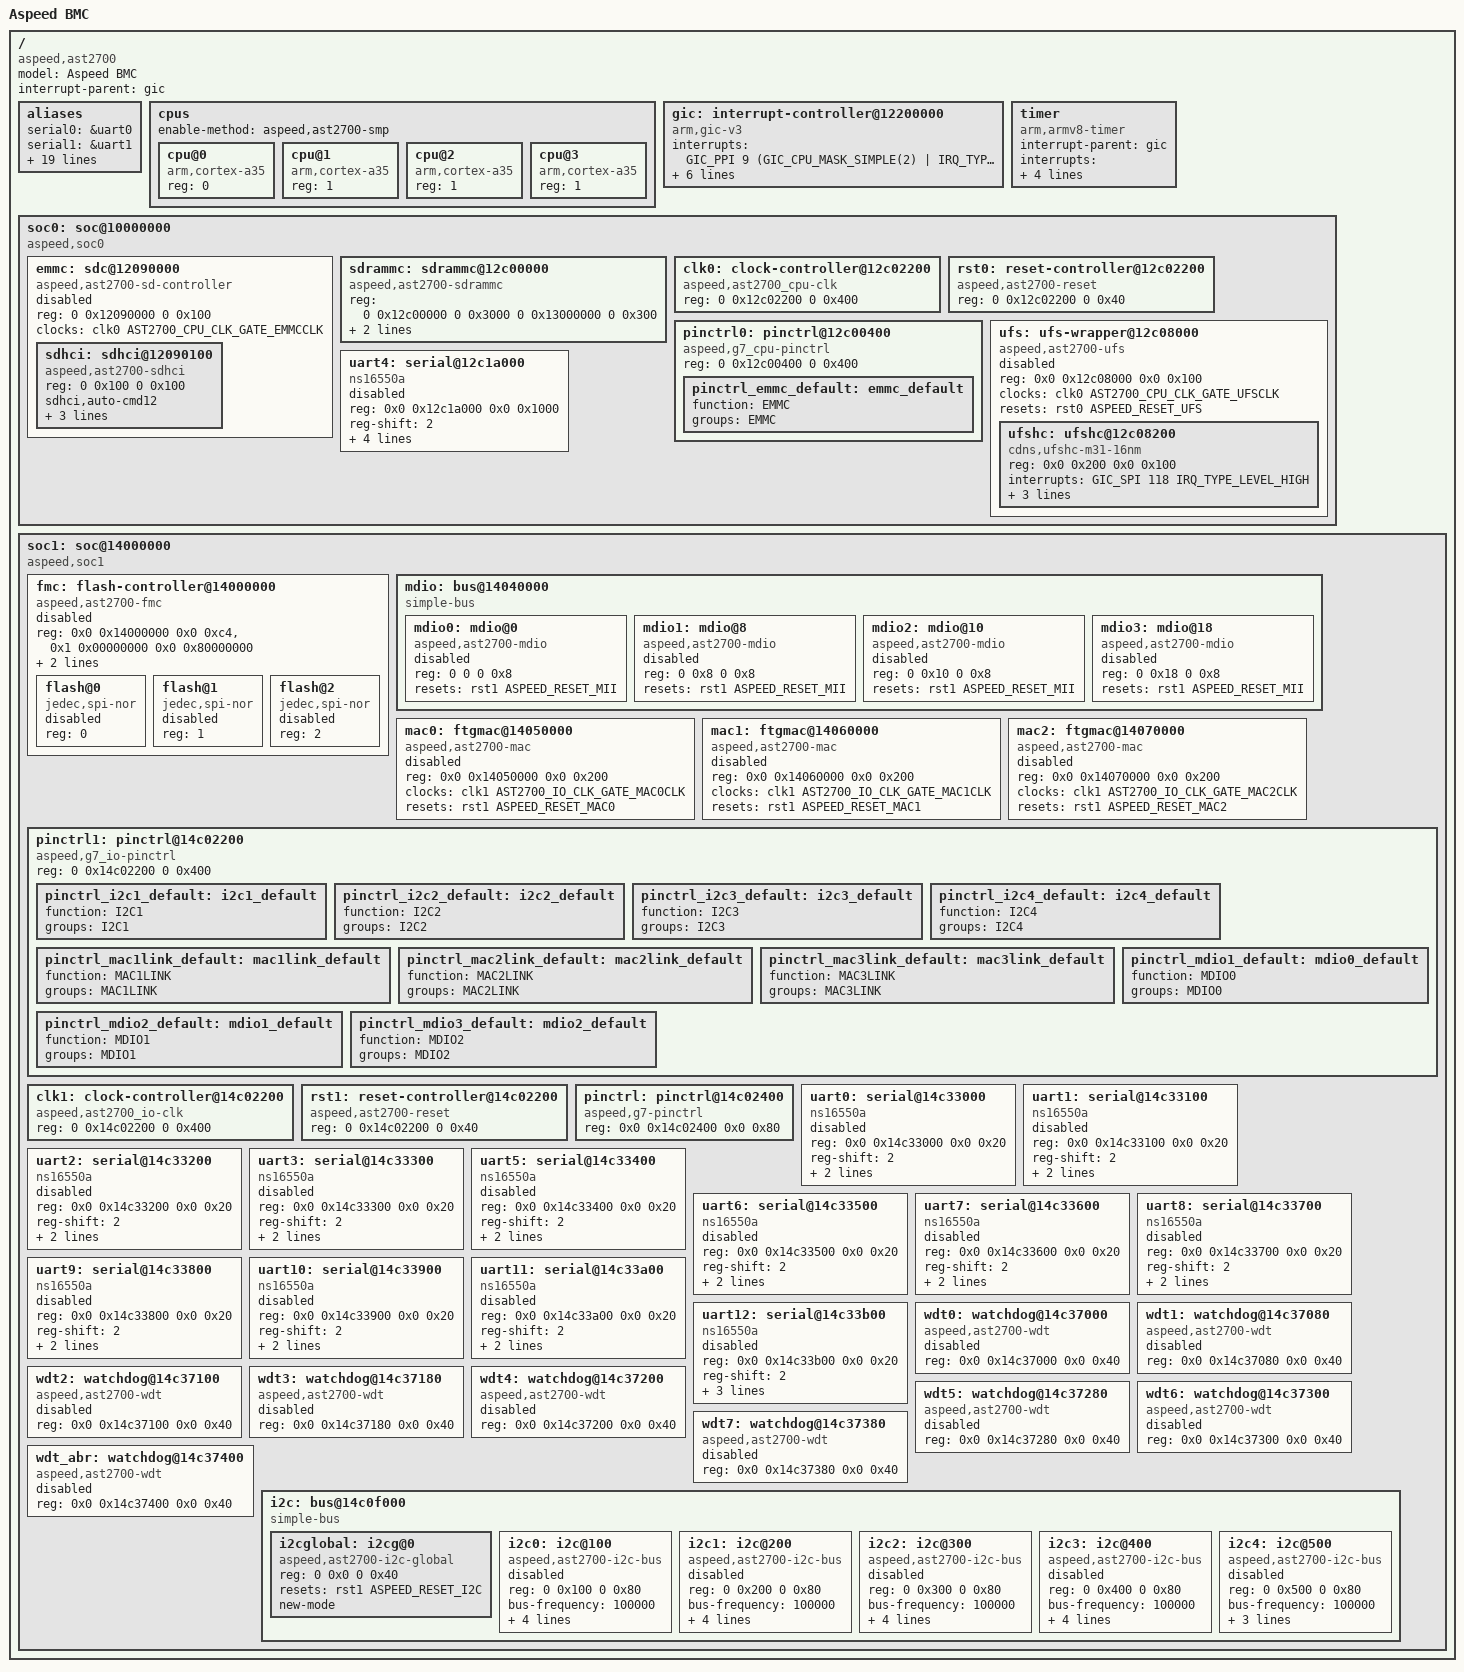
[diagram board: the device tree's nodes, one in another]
// SPDX-License-Identifier: GPL-2.0+
#include <dt-bindings/interrupt-controller/arm-gic.h>
#include <dt-bindings/gpio/aspeed-gpio.h>
#include <dt-bindings/clock/ast2700-clock.h>
#include <dt-bindings/reset/ast2700-reset.h>
#include "skeleton.dtsi"

/ {
	model = "Aspeed BMC";
	compatible = "aspeed,ast2700";
	#address-cells = <2>;
	#size-cells = <2>;
	interrupt-parent = <&gic>;

	aliases {
		serial0 = &uart0;
		serial1 = &uart1;
		serial2 = &uart2;
		serial3 = &uart3;
		serial4 = &uart4;
		serial5 = &uart5;
		serial6 = &uart6;
		serial7 = &uart7;
		serial8 = &uart8;
		serial9 = &uart9;
		serial10 = &uart10;
		serial11 = &uart11;
		serial12 = &uart12;
		i2c0 = &i2c0;
		i2c1 = &i2c1;
		i2c2 = &i2c2;
		i2c3 = &i2c3;
		i2c4 = &i2c4;
		ethernet0 = &mac0;
		ethernet1 = &mac1;
		ethernet2 = &mac2;
	};

	cpus {
		#address-cells = <1>;
		#size-cells = <0>;
		enable-method = "aspeed,ast2700-smp";

		cpu@0 {
			compatible = "arm,cortex-a35";
			device_type = "cpu";
			reg = <0>;
		};

		cpu@1 {
			compatible = "arm,cortex-a35";
			device_type = "cpu";
			reg = <1>;
		};

		cpu@2 {
			compatible = "arm,cortex-a35";
			device_type = "cpu";
			reg = <1>;
		};

		cpu@3 {
			compatible = "arm,cortex-a35";
			device_type = "cpu";
			reg = <1>;
		};

	};

	gic: interrupt-controller@12200000 {
		compatible = "arm,gic-v3";
		interrupts = <GIC_PPI 9 (GIC_CPU_MASK_SIMPLE(2) | IRQ_TYPE_LEVEL_HIGH)>;
		#interrupt-cells = <3>;
		interrupt-controller;
		interrupt-parent = <&gic>;
		#redistributor-regions = <1>;
		reg =	<0 0x12200000 0 0x10000>,		//GICD
			<0 0x12280000 0 0x80000>,		//GICR
			<0 0x40440000 0 0x1000>;		//GICC
	};

	timer {
		compatible = "arm,armv8-timer";
		interrupt-parent = <&gic>;
		interrupts = <GIC_PPI 13 (GIC_CPU_MASK_SIMPLE(2) | IRQ_TYPE_LEVEL_LOW)>,
				<GIC_PPI 14 (GIC_CPU_MASK_SIMPLE(2) | IRQ_TYPE_LEVEL_LOW)>,
				<GIC_PPI 11 (GIC_CPU_MASK_SIMPLE(2) | IRQ_TYPE_LEVEL_LOW)>,
				<GIC_PPI 10 (GIC_CPU_MASK_SIMPLE(2) | IRQ_TYPE_LEVEL_LOW)>;
	};

	soc0: soc@10000000 {
		compatible = "aspeed,soc0","simple-bus";
		#address-cells = <2>;
		#size-cells = <2>;
		ranges;

		emmc: sdc@12090000 {
			compatible = "aspeed,ast2700-sd-controller";
			reg = <0 0x12090000 0 0x100>;
			#address-cells = <2>;
			#size-cells = <2>;
			ranges = <0 0 0 0x12090000 0 0x10000>;
			clocks = <&clk0 AST2700_CPU_CLK_GATE_EMMCCLK>;
			status = "disable";

			sdhci: sdhci@12090100 {
				compatible = "aspeed,ast2700-sdhci";
				reg = <0 0x100 0 0x100>;
				sdhci,auto-cmd12;
				#interrupts = <GIC_SPI 15 IRQ_TYPE_LEVEL_HIGH>;
				clocks = <&clk0 AST2700_CPU_CLK_EMMC>;
				resets = <&rst0 ASPEED_RESET_EMMC>;
				//pinctrl-names = "default";
				//pinctrl-0 = <&pinctrl_emmc_default>;
			};
		};

		sdrammc: sdrammc@12c00000 {
			compatible = "aspeed,ast2700-sdrammc";
			reg = <0 0x12c00000 0 0x3000 0 0x13000000 0 0x300 >;
			clocks = <&clk0 AST2700_CPU_CLK_MPLL>;
			resets = <&rst0 ASPEED_RESET_SDRAM>;
		};

		clk0: clock-controller@12c02200 {
			compatible = "aspeed,ast2700_cpu-clk";
			reg = <0 0x12c02200 0 0x400>;
			#clock-cells = <1>;
		};

		rst0: reset-controller@12c02200 {
			compatible = "aspeed,ast2700-reset";
			reg = <0 0x12c02200 0 0x40>;
			#reset-cells = <1>;
		};

		pinctrl0: pinctrl@12c00400 {
			compatible = "aspeed,g7_cpu-pinctrl";
			reg = <0 0x12c00400 0 0x400>;
		};

		ufs: ufs-wrapper@12c08000 {
			compatible = "aspeed,ast2700-ufs";
			reg = <0x0 0x12c08000 0x0 0x100>;
			#address-cells = <2>;
			#size-cells = <2>;
			ranges = <0 0 0 0x12c08000 0 0x400>;
			clocks = <&clk0 AST2700_CPU_CLK_GATE_UFSCLK>;
			resets = <&rst0 ASPEED_RESET_UFS>;
			status = "disable";

			ufshc: ufshc@12c08200 {
				compatible = "cdns,ufshc-m31-16nm", "jedec,ufs-2.0";
				reg = <0x0 0x200 0x0 0x100>;
				interrupts = <GIC_SPI 118 IRQ_TYPE_LEVEL_HIGH>;
				freq-table-hz = <24000000 24000000>;
				clocks = <&clk0 AST2700_CPU_CLK_MPLL>;
				clock-names = "core_clk";
				dma-coherent;
			};
		};

		uart4: serial@12c1a000 {
			compatible = "ns16550a";
			reg = <0x0 0x12c1a000 0x0 0x1000>;
			reg-shift = <2>;
			interrupts = <GIC_SPI 36 IRQ_TYPE_LEVEL_HIGH>;
			clocks = <&clk1 AST2700_CPU_CLK_GATE_UART4CLK>;
			clock-frequency = <1846154>;
			no-loopback-test;
			status = "disabled";
		};
	};

	soc1: soc@14000000 {
		compatible = "aspeed,soc1","simple-bus";
		#address-cells = <2>;
		#size-cells = <2>;
		ranges;

		fmc: flash-controller@14000000 {
			reg = <0x0 0x14000000 0x0 0xc4>,
			      <0x1 0x00000000 0x0 0x80000000>;
			#address-cells = <1>;
			#size-cells = <0>;
			compatible = "aspeed,ast2700-fmc";
			status = "disabled";
			clocks = <&clk1 AST2700_IO_CLK_AHB>;
			num-cs = <3>;

			flash@0 {
				reg = <0>;
				compatible = "jedec,spi-nor";
				status = "disabled";
			};

			flash@1 {
				reg = <1>;
				compatible = "jedec,spi-nor";
				status = "disabled";
			};

			flash@2 {
				reg = <2>;
				compatible = "jedec,spi-nor";
				status = "disabled";
			};
		};

		mdio: bus@14040000 {
			compatible = "simple-bus";
			#address-cells = <2>;
			#size-cells = <2>;
			ranges = <0 0 0 0x14040000 0 0x100>;

			mdio0: mdio@0 {
				compatible = "aspeed,ast2700-mdio";
				reg = <0 0 0 0x8>;
				resets = <&rst1 ASPEED_RESET_MII>;
				status = "disabled";
			};

			mdio1: mdio@8 {
				compatible = "aspeed,ast2700-mdio";
				reg = <0 0x8 0 0x8>;
				resets = <&rst1 ASPEED_RESET_MII>;
				status = "disabled";
			};

			mdio2: mdio@10 {
				compatible = "aspeed,ast2700-mdio";
				reg = <0 0x10 0 0x8>;
				resets = <&rst1 ASPEED_RESET_MII>;
				status = "disabled";
			};

			mdio3: mdio@18 {
				compatible = "aspeed,ast2700-mdio";
				reg = <0 0x18 0 0x8>;
				resets = <&rst1 ASPEED_RESET_MII>;
				status = "disabled";
			};
		};

		mac0: ftgmac@14050000 {
			compatible = "aspeed,ast2700-mac", "faraday,ftgmac100";
			reg = <0x0 0x14050000 0x0 0x200>;
			clocks = <&clk1 AST2700_IO_CLK_GATE_MAC0CLK>;
			resets = <&rst1 ASPEED_RESET_MAC0>;
			status = "disabled";
		};

		mac1: ftgmac@14060000 {
			compatible = "aspeed,ast2700-mac", "faraday,ftgmac100";
			reg = <0x0 0x14060000 0x0 0x200>;
			clocks = <&clk1 AST2700_IO_CLK_GATE_MAC1CLK>;
			resets = <&rst1 ASPEED_RESET_MAC1>;
			status = "disabled";
		};

		mac2: ftgmac@14070000 {
			compatible = "aspeed,ast2700-mac", "faraday,ftgmac100";
			reg = <0x0 0x14070000 0x0 0x200>;
			clocks = <&clk1 AST2700_IO_CLK_GATE_MAC2CLK>;
			resets = <&rst1 ASPEED_RESET_MAC2>;
			status = "disabled";
		};

		pinctrl1: pinctrl@14c02200 {
			compatible = "aspeed,g7_io-pinctrl";
			reg = <0 0x14c02200 0 0x400>;
		};

		clk1: clock-controller@14c02200 {
			compatible = "aspeed,ast2700_io-clk";
			reg = <0 0x14c02200 0 0x400>;
			#clock-cells = <1>;
		};

		rst1: reset-controller@14c02200 {
			compatible = "aspeed,ast2700-reset";
			reg = <0 0x14c02200 0 0x40>;
			#reset-cells = <1>;
		};

		pinctrl: pinctrl@14c02400 {
			compatible = "aspeed,g7-pinctrl";
			reg = <0x0 0x14c02400 0x0 0x80>;
		};

		uart0: serial@14c33000 {
			compatible = "ns16550a";
			reg = <0x0 0x14c33000 0x0 0x20>;
			reg-shift = <2>;
			clocks = <&clk1 AST2700_IO_CLK_GATE_UART0CLK>;
			no-loopback-test;
			status = "disabled";
		};

		uart1: serial@14c33100 {
			compatible = "ns16550a";
			reg = <0x0 0x14c33100 0x0 0x20>;
			reg-shift = <2>;
			clocks = <&clk1 AST2700_IO_CLK_GATE_UART1CLK>;
			no-loopback-test;
			status = "disabled";
		};

		uart2: serial@14c33200 {
			compatible = "ns16550a";
			reg = <0x0 0x14c33200 0x0 0x20>;
			reg-shift = <2>;
			clocks = <&clk1 AST2700_IO_CLK_GATE_UART2CLK>;
			no-loopback-test;
			status = "disabled";
		};

		uart3: serial@14c33300 {
			compatible = "ns16550a";
			reg = <0x0 0x14c33300 0x0 0x20>;
			reg-shift = <2>;
			clocks = <&clk1 AST2700_IO_CLK_GATE_UART3CLK>;
			no-loopback-test;
			status = "disabled";
		};

		uart5: serial@14c33400 {
			compatible = "ns16550a";
			reg = <0x0 0x14c33400 0x0 0x20>;
			reg-shift = <2>;
			clocks = <&clk1 AST2700_IO_CLK_GATE_UART5CLK>;
			no-loopback-test;
			status = "disabled";
		};

		uart6: serial@14c33500 {
			compatible = "ns16550a";
			reg = <0x0 0x14c33500 0x0 0x20>;
			reg-shift = <2>;
			clocks = <&clk1 AST2700_IO_CLK_GATE_UART6CLK>;
			no-loopback-test;
			status = "disabled";
		};

		uart7: serial@14c33600 {
			compatible = "ns16550a";
			reg = <0x0 0x14c33600 0x0 0x20>;
			reg-shift = <2>;
			clocks = <&clk1 AST2700_IO_CLK_GATE_UART7CLK>;
			no-loopback-test;
			status = "disabled";
		};

		uart8: serial@14c33700 {
			compatible = "ns16550a";
			reg = <0x0 0x14c33700 0x0 0x20>;
			reg-shift = <2>;
			clocks = <&clk1 AST2700_IO_CLK_GATE_UART8CLK>;
			no-loopback-test;
			status = "disabled";
		};

		uart9: serial@14c33800 {
			compatible = "ns16550a";
			reg = <0x0 0x14c33800 0x0 0x20>;
			reg-shift = <2>;
			clocks = <&clk1 AST2700_IO_CLK_GATE_UART9CLK>;
			no-loopback-test;
			status = "disabled";
		};

		uart10: serial@14c33900 {
			compatible = "ns16550a";
			reg = <0x0 0x14c33900 0x0 0x20>;
			reg-shift = <2>;
			clocks = <&clk1 AST2700_IO_CLK_GATE_UART10CLK>;
			no-loopback-test;
			status = "disabled";
		};

		uart11: serial@14c33a00 {
			compatible = "ns16550a";
			reg = <0x0 0x14c33a00 0x0 0x20>;
			reg-shift = <2>;
			clocks = <&clk1 AST2700_IO_CLK_GATE_UART11CLK>;
			no-loopback-test;
			status = "disabled";
		};

		uart12: serial@14c33b00 {
			compatible = "ns16550a";
			reg = <0x0 0x14c33b00 0x0 0x20>;
			reg-shift = <2>;
			clocks = <&clk1 AST2700_IO_CLK_GATE_UART12CLK>;
			clock-frequency = <1846154>;
			no-loopback-test;
			status = "disabled";
		};

		wdt0: watchdog@14c37000 {
			compatible = "aspeed,ast2700-wdt";
			reg = <0x0 0x14c37000 0x0 0x40>;
			status = "disabled";
		};

		wdt1: watchdog@14c37080 {
			compatible = "aspeed,ast2700-wdt";
			reg = <0x0 0x14c37080 0x0 0x40>;
			status = "disabled";
		};

		wdt2: watchdog@14c37100 {
			compatible = "aspeed,ast2700-wdt";
			reg = <0x0 0x14c37100 0x0 0x40>;
			status = "disabled";
		};

		wdt3: watchdog@14c37180 {
			compatible = "aspeed,ast2700-wdt";
			reg = <0x0 0x14c37180 0x0 0x40>;
			status = "disabled";
		};

		wdt4: watchdog@14c37200 {
			compatible = "aspeed,ast2700-wdt";
			reg = <0x0 0x14c37200 0x0 0x40>;
			status = "disabled";
		};

		wdt5: watchdog@14c37280 {
			compatible = "aspeed,ast2700-wdt";
			reg = <0x0 0x14c37280 0x0 0x40>;
			status = "disabled";
		};

		wdt6: watchdog@14c37300 {
			compatible = "aspeed,ast2700-wdt";
			reg = <0x0 0x14c37300 0x0 0x40>;
			status = "disabled";
		};

		wdt7: watchdog@14c37380 {
			compatible = "aspeed,ast2700-wdt";
			reg = <0x0 0x14c37380 0x0 0x40>;
			status = "disabled";
		};

		wdt_abr: watchdog@14c37400 {
			compatible = "aspeed,ast2700-wdt";
			reg = <0x0 0x14c37400 0x0 0x40>;
			status = "disabled";
		};

		i2c: bus@14c0f000 {
			compatible = "simple-bus";
			#address-cells = <2>;
			#size-cells = <2>;
			ranges = <0 0 0 0x14c0f000 0 0x1100>;
		};
	};
};

&i2c {
	i2cglobal: i2cg@0 {
	#address-cells = <1>;
	#size-cells = <0>;

		compatible = "aspeed,ast2700-i2c-global";
		reg = <0 0x0 0 0x40>;
		resets = <&rst1 ASPEED_RESET_I2C>;
		new-mode;
	};

	i2c0: i2c@100 {
		#address-cells = <1>;
		#size-cells = <0>;
		#interrupt-cells = <1>;

		reg = <0 0x100 0 0x80>;
		compatible = "aspeed,ast2700-i2c-bus";
		bus-frequency = <100000>;
		interrupts = <GIC_SPI 110 IRQ_TYPE_LEVEL_HIGH>;
		resets = <&rst1 ASPEED_RESET_I2C>;
		clocks = <&clk1 AST2700_IO_CLK_APB>;
		pinctrl-names = "default";
		pinctrl-0 = <&pinctrl_i2c1_default>;
		status = "disabled";
	};

	i2c1: i2c@200 {
		#address-cells = <1>;
		#size-cells = <0>;
		#interrupt-cells = <1>;

		reg = <0 0x200 0 0x80>;
		compatible = "aspeed,ast2700-i2c-bus";
		bus-frequency = <100000>;
		interrupts = <GIC_SPI 111 IRQ_TYPE_LEVEL_HIGH>;
		resets = <&rst1 ASPEED_RESET_I2C>;
		clocks = <&clk1 AST2700_IO_CLK_APB>;
		pinctrl-names = "default";
		pinctrl-0 = <&pinctrl_i2c2_default>;
		status = "disabled";
	};

	i2c2: i2c@300 {
		#address-cells = <1>;
		#size-cells = <0>;
		#interrupt-cells = <1>;

		reg = <0 0x300 0 0x80>;
		compatible = "aspeed,ast2700-i2c-bus";
		bus-frequency = <100000>;
		interrupts = <GIC_SPI 112 IRQ_TYPE_LEVEL_HIGH>;
		resets = <&rst1 ASPEED_RESET_I2C>;
		clocks = <&clk1 AST2700_IO_CLK_APB>;
		pinctrl-names = "default";
		pinctrl-0 = <&pinctrl_i2c3_default>;
		status = "disabled";
	};

	i2c3: i2c@400 {
		#address-cells = <1>;
		#size-cells = <0>;
		#interrupt-cells = <1>;

		reg = <0 0x400 0 0x80>;
		compatible = "aspeed,ast2700-i2c-bus";
		bus-frequency = <100000>;
		interrupts = <GIC_SPI 113 IRQ_TYPE_LEVEL_HIGH>;
		resets = <&rst1 ASPEED_RESET_I2C>;
		clocks = <&clk1 AST2700_IO_CLK_APB>;
		pinctrl-names = "default";
		pinctrl-0 = <&pinctrl_i2c4_default>;
		status = "disabled";
	};

	i2c4: i2c@500 {
		#address-cells = <1>;
		#size-cells = <0>;
		#interrupt-cells = <1>;

		reg = <0 0x500 0 0x80>;
		compatible = "aspeed,ast2700-i2c-bus";
		bus-frequency = <100000>;
		interrupts = <GIC_SPI 114 IRQ_TYPE_LEVEL_HIGH>;
		resets = <&rst1 ASPEED_RESET_I2C>;
		clocks = <&clk1 AST2700_IO_CLK_APB>;
		pinctrl-names = "default";
		status = "disabled";
	};
};

&pinctrl0 {
	pinctrl_emmc_default: emmc_default {
		function = "EMMC";
		groups = "EMMC";
	};
};

&pinctrl1 {
	pinctrl_i2c1_default: i2c1_default {
		function = "I2C1";
		groups = "I2C1";
	};

	pinctrl_i2c2_default: i2c2_default {
		function = "I2C2";
		groups = "I2C2";
	};

	pinctrl_i2c3_default: i2c3_default {
		function = "I2C3";
		groups = "I2C3";
	};

	pinctrl_i2c4_default: i2c4_default {
		function = "I2C4";
		groups = "I2C4";
	};

	pinctrl_mac1link_default: mac1link_default {
		function = "MAC1LINK";
		groups = "MAC1LINK";
	};

	pinctrl_mac2link_default: mac2link_default {
		function = "MAC2LINK";
		groups = "MAC2LINK";
	};

	pinctrl_mac3link_default: mac3link_default {
		function = "MAC3LINK";
		groups = "MAC3LINK";
	};

	pinctrl_mdio1_default: mdio0_default {
		function = "MDIO0";
		groups = "MDIO0";
	};

	pinctrl_mdio2_default: mdio1_default {
		function = "MDIO1";
		groups = "MDIO1";
	};

	pinctrl_mdio3_default: mdio2_default {
		function = "MDIO2";
		groups = "MDIO2";
	};

};
